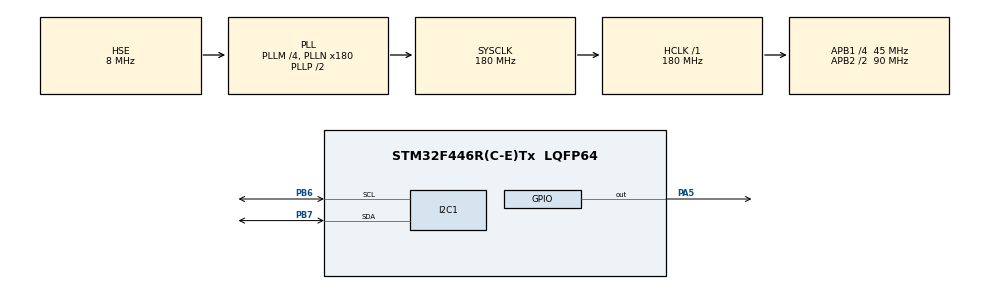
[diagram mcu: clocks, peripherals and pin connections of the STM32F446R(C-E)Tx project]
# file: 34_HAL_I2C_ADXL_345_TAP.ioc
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Mcu.Family=STM32F4
Mcu.Name=STM32F446R(C-E)Tx
Mcu.Package=LQFP64
NVIC.PriorityGroup=NVIC_PRIORITYGROUP_4
PA5.Signal=GPIO_Output
PB6.Mode=I2C
PB6.Signal=I2C1_SCL
PB7.Mode=I2C
PB7.Signal=I2C1_SDA
PH0-OSC_IN.Mode=HSE-External-Oscillator
PH0-OSC_IN.Signal=RCC_OSC_IN
PH1-OSC_OUT.Mode=HSE-External-Oscillator
PH1-OSC_OUT.Signal=RCC_OSC_OUT
ProjectManager.HeapSize=0x200
ProjectManager.StackSize=0x400
ProjectManager.TargetToolchain=STM32CubeIDE
RCC.AHBFreq_Value=180000000
RCC.APB1CLKDivider=RCC_HCLK_DIV4
RCC.APB1Freq_Value=45000000
RCC.APB1TimFreq_Value=90000000
RCC.APB2CLKDivider=RCC_HCLK_DIV2
RCC.APB2Freq_Value=90000000
RCC.APB2TimFreq_Value=180000000
RCC.CortexFreq_Value=180000000
RCC.HCLKFreq_Value=180000000
RCC.HSE_VALUE=8000000
RCC.PLLM=4
RCC.PLLN=180
RCC.PLLSourceVirtual=RCC_PLLSOURCE_HSE
RCC.SYSCLKFreq_VALUE=180000000
RCC.SYSCLKSource=RCC_SYSCLKSOURCE_PLLCLK
RCC.USBFreq_Value=180000000
RCC.VCOOutputFreq_Value=360000000
board=custom

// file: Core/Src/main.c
/* USER CODE BEGIN Header */
/**
  ******************************************************************************
  * @file           : main.c
  * @brief          : Main program body
  ******************************************************************************
  * @attention
  *
  * <h2><center>&copy; Copyright (c) 2022 STMicroelectronics.
  * All rights reserved.</center></h2>
  *
  * This software component is licensed by ST under BSD 3-Clause license,
  * the "License"; You may not use this file except in compliance with the
  * License. You may obtain a copy of the License at:
  *                        opensource.org/licenses/BSD-3-Clause
  *
  ******************************************************************************
  */
/* USER CODE END Header */
#include "main.h"

/* USER CODE BEGIN Includes */
#define ADXL_Address 0x53 << 1
/* USER CODE END Includes */

I2C_HandleTypeDef hi2c1;

/* USER CODE BEGIN PV */
uint8_t status;
uint8_t data_rec;
/* USER CODE END PV */

void SystemClock_Config(void);
static void MX_GPIO_Init(void);
static void MX_I2C1_Init(void);

/* USER CODE BEGIN PFP */
void Scan_I2C_Slave_address();
void ADXL_Init();
void ADXL_write(uint8_t reg, uint8_t value);
uint8_t ADXL_read(uint8_t reg, uint8_t numOfBytes);
/* USER CODE END PFP */

int main(void)
{

  /* MCU Configuration--------------------------------------------------------*/

  /* Reset of all peripherals, Initializes the Flash interface and the Systick. */
  HAL_Init();

  /* Configure the system clock */
  SystemClock_Config();

  /* Initialize all configured peripherals */
  MX_GPIO_Init();
  MX_I2C1_Init();

  /* Infinite loop */
  while (1)
  {
	  status = ADXL_read(0x30, 1); // interrupt source register(0x30)

	  if((status >> 5) & 0x01)
		  HAL_GPIO_WritePin(GPIOA, GPIO_PIN_5, GPIO_PIN_SET); //single Tap

	  else if ((status >> 6 ) & 0x01)
		  HAL_GPIO_WritePin(GPIOA, GPIO_PIN_5, GPIO_PIN_RESET); // Double Tap
  }
}

void SystemClock_Config(void)
{
  RCC_OscInitTypeDef RCC_OscInitStruct = {0};
  RCC_ClkInitTypeDef RCC_ClkInitStruct = {0};

  /** Configure the main internal regulator output voltage
  */
  __HAL_RCC_PWR_CLK_ENABLE();
  __HAL_PWR_VOLTAGESCALING_CONFIG(PWR_REGULATOR_VOLTAGE_SCALE1);
  /** Initializes the RCC Oscillators according to the specified parameters
  * in the RCC_OscInitTypeDef structure.
  */
  RCC_OscInitStruct.OscillatorType = RCC_OSCILLATORTYPE_HSE;
  RCC_OscInitStruct.HSEState = RCC_HSE_ON;
  RCC_OscInitStruct.PLL.PLLState = RCC_PLL_ON;
  RCC_OscInitStruct.PLL.PLLSource = RCC_PLLSOURCE_HSE;
  RCC_OscInitStruct.PLL.PLLM = 4;
  RCC_OscInitStruct.PLL.PLLN = 180;
  RCC_OscInitStruct.PLL.PLLP = RCC_PLLP_DIV2;
  RCC_OscInitStruct.PLL.PLLQ = 2;
  RCC_OscInitStruct.PLL.PLLR = 2;
  if (HAL_RCC_OscConfig(&RCC_OscInitStruct) != HAL_OK)
  {
    Error_Handler();
  }
  /** Activate the Over-Drive mode
  */
  if (HAL_PWREx_EnableOverDrive() != HAL_OK)
  {
    Error_Handler();
  }
  /** Initializes the CPU, AHB and APB buses clocks
  */
  RCC_ClkInitStruct.ClockType = RCC_CLOCKTYPE_HCLK|RCC_CLOCKTYPE_SYSCLK
                              |RCC_CLOCKTYPE_PCLK1|RCC_CLOCKTYPE_PCLK2;
  RCC_ClkInitStruct.SYSCLKSource = RCC_SYSCLKSOURCE_PLLCLK;
  RCC_ClkInitStruct.AHBCLKDivider = RCC_SYSCLK_DIV1;
  RCC_ClkInitStruct.APB1CLKDivider = RCC_HCLK_DIV4;
  RCC_ClkInitStruct.APB2CLKDivider = RCC_HCLK_DIV2;

  if (HAL_RCC_ClockConfig(&RCC_ClkInitStruct, FLASH_LATENCY_5) != HAL_OK)
  {
    Error_Handler();
  }
}

static void MX_I2C1_Init(void)
{

  hi2c1.Instance = I2C1;
  hi2c1.Init.ClockSpeed = 100000;
  hi2c1.Init.DutyCycle = I2C_DUTYCYCLE_2;
  hi2c1.Init.OwnAddress1 = 0;
  hi2c1.Init.AddressingMode = I2C_ADDRESSINGMODE_7BIT;
  hi2c1.Init.DualAddressMode = I2C_DUALADDRESS_DISABLE;
  hi2c1.Init.OwnAddress2 = 0;
  hi2c1.Init.GeneralCallMode = I2C_GENERALCALL_DISABLE;
  hi2c1.Init.NoStretchMode = I2C_NOSTRETCH_DISABLE;
  if (HAL_I2C_Init(&hi2c1) != HAL_OK)
  {
    Error_Handler();
  }

}

static void MX_GPIO_Init(void)
{
  GPIO_InitTypeDef GPIO_InitStruct = {0};

  /* GPIO Ports Clock Enable */
  __HAL_RCC_GPIOH_CLK_ENABLE();
  __HAL_RCC_GPIOA_CLK_ENABLE();
  __HAL_RCC_GPIOB_CLK_ENABLE();

  /*Configure GPIO pin Output Level */
  HAL_GPIO_WritePin(GPIOA, GPIO_PIN_5, GPIO_PIN_RESET);

  /*Configure GPIO pin : PA5 */
  GPIO_InitStruct.Pin = GPIO_PIN_5;
  GPIO_InitStruct.Mode = GPIO_MODE_OUTPUT_PP;
  GPIO_InitStruct.Pull = GPIO_NOPULL;
  GPIO_InitStruct.Speed = GPIO_SPEED_FREQ_LOW;
  HAL_GPIO_Init(GPIOA, &GPIO_InitStruct);

}

/* USER CODE BEGIN 4 */
void Scan_I2C_Slave_address()
{
	for (int i = 0; i < 256; ++i)
	{
		if (HAL_I2C_IsDeviceReady(&hi2c1, i, 1, 10) == HAL_OK)
		{
			HAL_GPIO_TogglePin(GPIOA, GPIO_PIN_5);
			break;
		}
	}
}

void ADXL_write(uint8_t reg, uint8_t value)
{
	uint8_t data[2];
	data[0] = reg;
	data[1] = value;
	HAL_I2C_Master_Transmit(&hi2c1, ADXL_Address, data, 2, 10);
}

uint8_t ADXL_read(uint8_t reg, uint8_t numOfBytes)
{
	HAL_I2C_Mem_Read(&hi2c1, ADXL_Address, reg, 1, data_rec, numOfBytes, 10);
	return data_rec;
}

void ADXL_Init()
{
	//Sensörden okuma işlemini başlatmak için öncelikle power_ctrl bitlerini resetledik.
	ADXL_write(0x2D, 0);

	//sensörün ölçüm bitlerini set, wake up bitini reset ve frekansını 8mhz ayarlayarak ölçüm yapmaya hazır hale getirdik
	ADXL_write(0x2D, 0x08);

	//Z eksenini basma için etkinleştiriyoruz
	ADXL_write(0x2A, 0x01);

	//Tek basma eşiğini ayarlıyorum. Gireceğiniz değer ile 62.5mg/LSB çarpılarak g değeri hesaplanır. Örneğin 40*0.0625 = 2.5g
	ADXL_write(0x1D, 40);

	// Tek basma süresini ayarlıyorum. Gireceğiniz değer ile 625uS/LSB çarpılarak eşik süresi ayarlanır. Örneğin 32*0.000625 = 0.02s
	// bu değer gelen bir etkileşimin dokunma etkileşimi olması için geçmesi gereken maksimum süreyi belirler. DUR register'a yazılır.
	ADXL_write(0x21, 32);

	// Dokunma gecikmesini ayarlıyorum. 0.1sn'ye ayarlıyorum. Girilen değeri, 1.25ms/LSB ile çarparak gecikme süresi elde edilir. 80*0.00125
	ADXL_write(0x22, 80);

	// Dokunma penceresi, WINDIW register'a 240 yazarak 0.3sn'ye ayarlıyorum. (.3 / .00125) Bu değer ikinci bir basmanın olabileceği, gecikme
	// süresinin sona ermesinden sonra geçen süreyi temsil eder.
	ADXL_write(0x23, 240);

	// INT1 pinini INT_MAP Register'a 0 yazarak etkinleştiriyorum.
	ADXL_write(0x2F, 0x00);

	// int enable reg
	ADXL_Write(0x2E, 0x60);	// Double Tap

}

/* USER CODE END 4 */

void Error_Handler(void)
{
  __disable_irq();
  while (1)
  {
  }
}

/************************ (C) COPYRIGHT STMicroelectronics *****END OF FILE****/
